VERSION ""

NS_ :

BS_:

BU_: receiver_node send_node

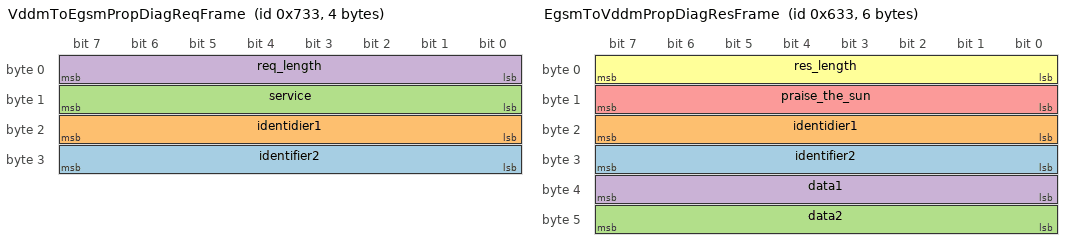
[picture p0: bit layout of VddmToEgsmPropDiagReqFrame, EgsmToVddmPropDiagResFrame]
BO_ 1843 VddmToEgsmPropDiagReqFrame: 4 Vector__XXX
 SG_ identifier2 : 31|8@0+ (1,0) [0|255] "" Vector__XXX
 SG_ identidier1 : 23|8@0+ (1,0) [0|255] "" Vector__XXX
 SG_ service : 15|8@0+ (1,0) [0|255] "" Vector__XXX
 SG_ req_length : 7|8@0+ (1,0) [0|8] "" Vector__XXX

BO_ 1587 EgsmToVddmPropDiagResFrame: 6 Vector__XXX
 SG_ identifier2 : 31|8@0+ (1,0) [0|255] ""  receiver_node
 SG_ identidier1 : 23|8@0+ (1,0) [0|255] ""  receiver_node
 SG_ data2 : 47|8@0+ (1,0) [0|255] ""  receiver_node
 SG_ data1 : 39|8@0+ (1,0) [0|255] ""  receiver_node
 SG_ praise_the_sun : 15|8@0+ (1,0) [0|255] ""  receiver_node
 SG_ res_length : 7|8@0+ (1,0) [0|255] ""  receiver_node

EV_ Sensor_Counter: 0 [1|5] "" 3 1 DUMMY_NODE_VECTOR0 Vector__XXX;

EV_ Mode_Select: 0 [0|2] "states" 0 2 DUMMY_NODE_VECTOR0 Vector__XXX;

EV_ gear: 0 [0|1000] "" 500 3 DUMMY_NODE_VECTOR0 Vector__XXX;

EV_ shift_down: 0 [0|1] "boolean" 0 4 DUMMY_NODE_VECTOR0 Vector__XXX;

EV_ shift_up: 0 [0|1] "boolean" 0 5 DUMMY_NODE_VECTOR0 Vector__XXX;

EV_ Gear_Down: 1 [0|1] "%" 0 6 DUMMY_NODE_VECTOR0 Vector__XXX;

EV_ Gear_up: 1 [0|1] "%" 0 7 DUMMY_NODE_VECTOR0 Vector__XXX;

EV_ Gear_Shift: 1 [0|1000] "%" 500 8 DUMMY_NODE_VECTOR0 Vector__XXX;

EV_ M_A: 0 [0|1] "Bit" 0 9 DUMMY_NODE_VECTOR0 Vector__XXX;

EV_ A_A: 0 [0|1] "Bit" 0 10 DUMMY_NODE_VECTOR0 Vector__XXX;

EV_ C_A: 0 [0|1] "Bit" 0 11 DUMMY_NODE_VECTOR0 Vector__XXX;

EV_ U_A: 0 [0|1] "Bit" 0 12 DUMMY_NODE_VECTOR0 Vector__XXX;

EV_ UU_A: 0 [0|1] "Bit" 0 13 DUMMY_NODE_VECTOR0 Vector__XXX;

EV_ N_A: 0 [0|1] "Bit" 0 14 DUMMY_NODE_VECTOR0 Vector__XXX;

EV_ M: 0 [0|1] "Bit" 0 15 DUMMY_NODE_VECTOR0 Vector__XXX;

EV_ A: 0 [0|1] "Bit" 0 16 DUMMY_NODE_VECTOR0 Vector__XXX;

EV_ C: 0 [0|1] "Bit" 0 17 DUMMY_NODE_VECTOR0 Vector__XXX;

EV_ N: 0 [0|1] "Bit" 0 18 DUMMY_NODE_VECTOR0 Vector__XXX;

EV_ U: 0 [0|1] "Bit" 0 19 DUMMY_NODE_VECTOR0 Vector__XXX;

EV_ UU: 0 [0|1] "Bit" 0 20 DUMMY_NODE_VECTOR0 Vector__XXX;

EV_ NN: 0 [0|1] "Bit" 0 21 DUMMY_NODE_VECTOR0 Vector__XXX;

EV_ NN_A: 0 [0|1] "Bit" 0 22 DUMMY_NODE_VECTOR0 Vector__XXX;

BA_DEF_  "BusType" STRING ;
BA_DEF_DEF_  "BusType" "";
BA_ "BusType" "CAN";
